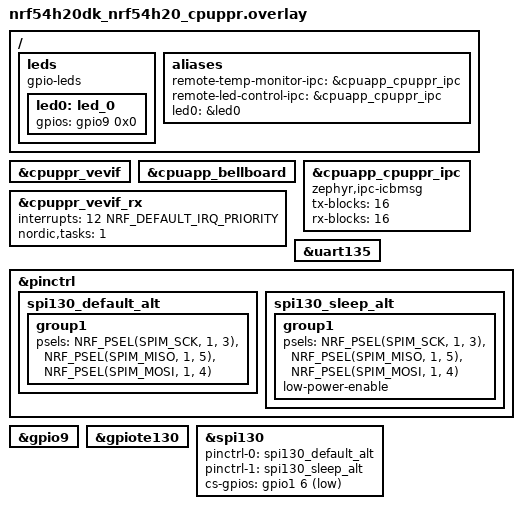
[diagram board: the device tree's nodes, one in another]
/*
 * Copyright (c) 2026 Nordic Semiconductor ASA
 * SPDX-License-Identifier: LicenseRef-Nordic-5-Clause
 */

&cpuppr_vevif {
	status = "okay";
};

&cpuapp_bellboard {
	status = "okay";
};

&cpuppr_vevif_rx {
	/* Only 1 interrupt is used. Remove 15 not used isr handlers (1.4k savings) */
	interrupts = <12 NRF_DEFAULT_IRQ_PRIORITY>;
	nordic,tasks = <1>;
};

&cpuapp_cpuppr_ipc {
	status = "okay";
	compatible = "zephyr,ipc-icbmsg";
	tx-blocks = <16>;
	rx-blocks = <16>;
};

&uart135 {
	/delete-property/ hw-flow-control;
};

/ {
	leds {
		compatible = "gpio-leds";

		led0: led_0 {
			gpios = <&gpio9 0x0 0x0>;
		};
	};

	aliases {
		remote-temp-monitor-ipc = &cpuapp_cpuppr_ipc;
		remote-led-control-ipc = &cpuapp_cpuppr_ipc;
		led0 = &led0;
	};
};

&pinctrl {
	spi130_default_alt: spi130_default_alt {
		group1 {
			psels = <NRF_PSEL(SPIM_SCK, 1, 3)>,
				<NRF_PSEL(SPIM_MISO, 1, 5)>,
				<NRF_PSEL(SPIM_MOSI, 1, 4)>;
		};
	};

	spi130_sleep_alt: spi130_sleep_alt {
		group1 {
			psels = <NRF_PSEL(SPIM_SCK, 1, 3)>,
				<NRF_PSEL(SPIM_MISO, 1, 5)>,
				<NRF_PSEL(SPIM_MOSI, 1, 4)>;
			low-power-enable;
		};
	};
};

&gpio9 {
	status = "okay";
	/delete-property/ gpiote-instance;
};

&gpiote130 {
	status = "okay";
};

app_spi: &spi130 {
	status = "okay";
	pinctrl-0 = <&spi130_default_alt>;
	pinctrl-1 = <&spi130_sleep_alt>;
	pinctrl-names = "default", "sleep";
	cs-gpios = <&gpio1 6 GPIO_ACTIVE_LOW>;
};
